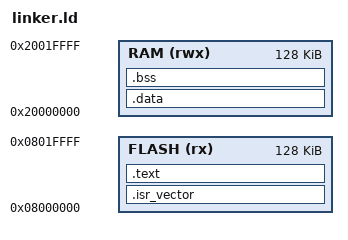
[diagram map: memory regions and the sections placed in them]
/*
 * linker.ld — STM32G474CBT6 memory layout
 *
 * Author: jayis1
 * License: GPL-2.0
 *
 * 128 KiB Flash @ 0x08000000, 128 KiB SRAM @ 0x20000000.
 * Stack at top of SRAM (0x20020000), set via --defsym=__stack in Makefile.
 */

ENTRY(Reset_Handler)

MEMORY
{
    FLASH (rx)  : ORIGIN = 0x08000000, LENGTH = 128K
    RAM   (rwx) : ORIGIN = 0x20000000, LENGTH = 128K
}

SECTIONS
{
    .isr_vector : {
        . = ALIGN(4);
        KEEP(*(.isr_vector))
        . = ALIGN(4);
    } > FLASH

    .text : {
        . = ALIGN(4);
        *(.text)
        *(.text.*)
        *(.rodata)
        *(.rodata.*)
        *(.glue_7)
        *(.glue_7t)
        . = ALIGN(4);
        _etext = .;
    } > FLASH

    .data : AT (_etext) {
        . = ALIGN(4);
        _sdata = .;
        *(.data)
        *(.data.*)
        . = ALIGN(4);
        _edata = .;
    } > RAM

    .bss : {
        . = ALIGN(4);
        _sbss = .;
        *(.bss)
        *(.bss.*)
        *(COMMON)
        . = ALIGN(4);
        _ebss = .;
    } > RAM

    _stack_top = ORIGIN(RAM) + LENGTH(RAM);
}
